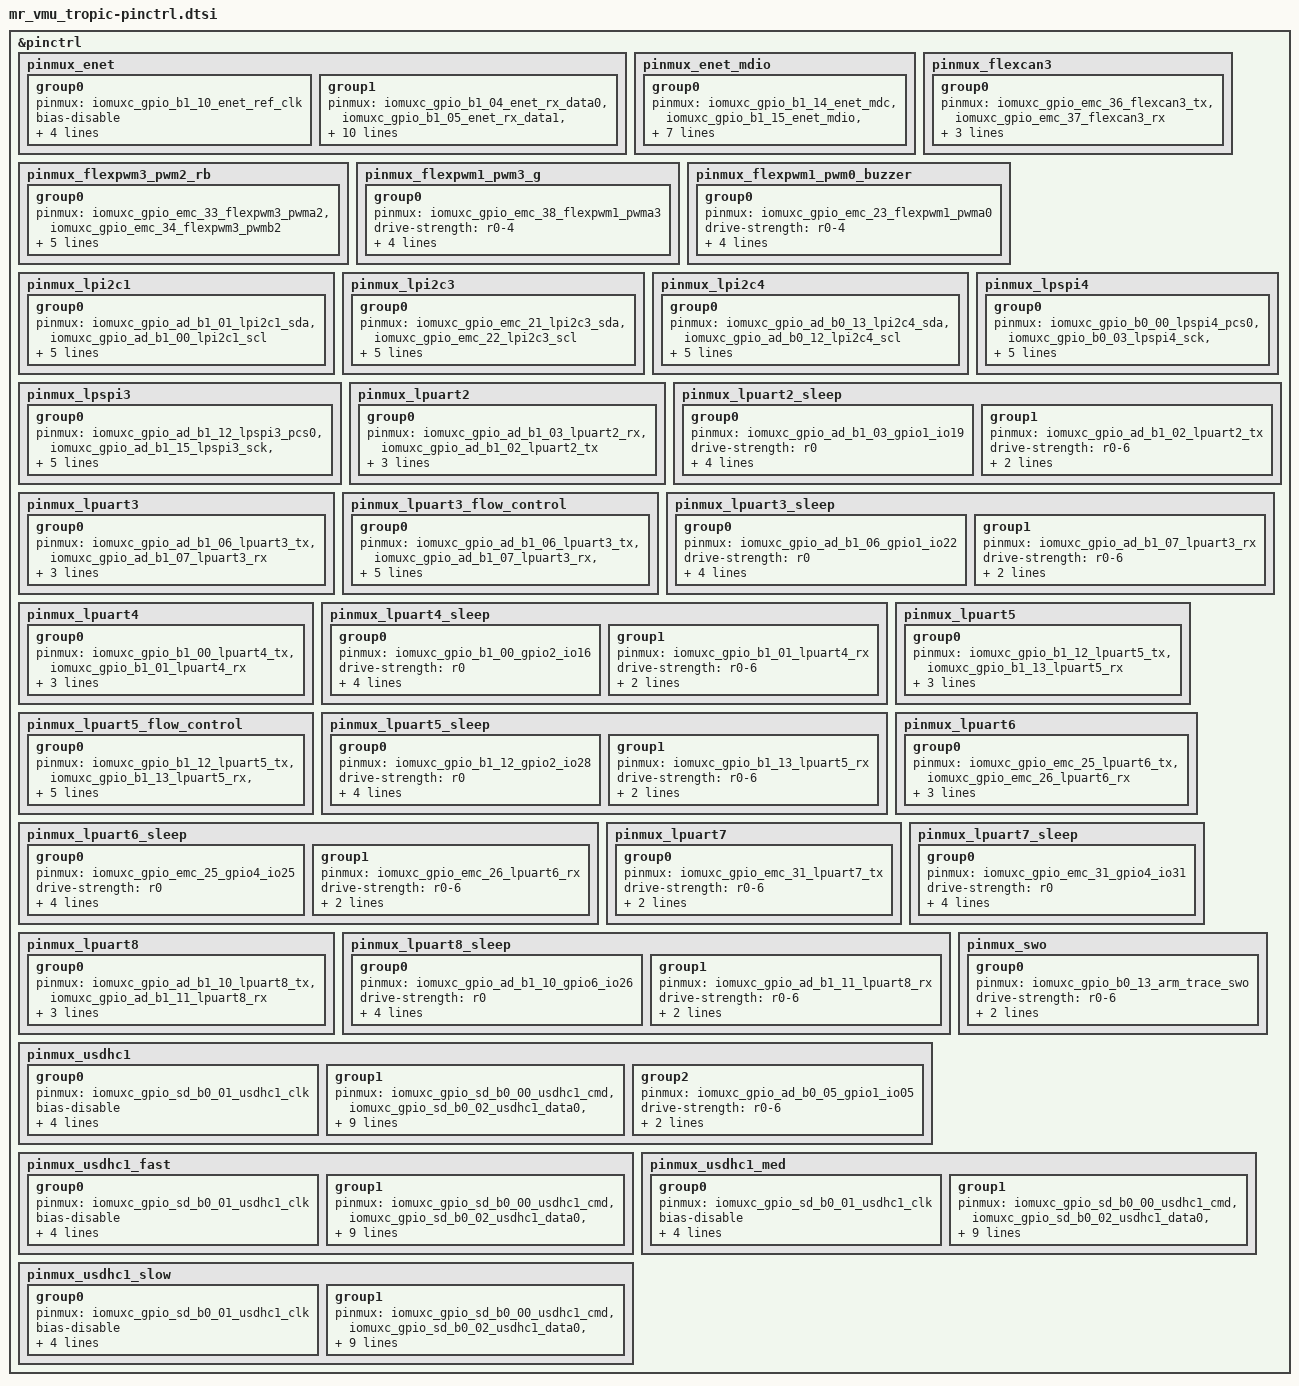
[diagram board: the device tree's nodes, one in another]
/*
 * Copyright (c) 2022, NXP
 * Copyright (c) 2026 CogniPilot Foundation
 * SPDX-License-Identifier: Apache-2.0
 *
 * Note: File generated by gen_board_pinctrl.py
 * from mr_vmu_tropic.mex
 */

#include <nxp/nxp_imx/rt/mimxrt1064dvl6a-pinctrl.dtsi>

&pinctrl {
	pinmux_enet: pinmux_enet {
		group0 {
			pinmux = <&iomuxc_gpio_b1_10_enet_ref_clk>;
			bias-disable;
			drive-strength = "r0-6";
			slew-rate = "fast";
			nxp,speed = "50-mhz";
			input-enable;
		};

		group1 {
			pinmux = <&iomuxc_gpio_b1_04_enet_rx_data0>,
				 <&iomuxc_gpio_b1_05_enet_rx_data1>,
				 <&iomuxc_gpio_b1_06_enet_rx_en>,
				 <&iomuxc_gpio_b1_07_enet_tx_data0>,
				 <&iomuxc_gpio_b1_08_enet_tx_data1>,
				 <&iomuxc_gpio_b1_09_enet_tx_en>,
				 <&iomuxc_gpio_b1_11_enet_rx_er>;
			drive-strength = "r0-5";
			bias-pull-up;
			bias-pull-up-value = "100k";
			slew-rate = "fast";
			nxp,speed = "200-mhz";
		};
	};

	pinmux_enet_mdio: pinmux_enet_mdio {
		group0 {
			pinmux = <&iomuxc_gpio_b1_14_enet_mdc>,
				 <&iomuxc_gpio_b1_15_enet_mdio>,
				 <&iomuxc_gpio_b0_14_gpio2_io14>,
				 <&iomuxc_gpio_b0_15_gpio2_io15>;
			drive-strength = "r0-5";
			bias-pull-up;
			bias-pull-up-value = "100k";
			slew-rate = "fast";
			nxp,speed = "200-mhz";
		};
	};

	pinmux_flexcan3: pinmux_flexcan3 {
		group0 {
			pinmux = <&iomuxc_gpio_emc_36_flexcan3_tx>,
				 <&iomuxc_gpio_emc_37_flexcan3_rx>;
			drive-strength = "r0-6";
			slew-rate = "slow";
			nxp,speed = "100-mhz";
		};
	};

	/* flexpwm output for board RGB Red/Blue LED */
	pinmux_flexpwm3_pwm2_rb: pinmux_flexpwm3_pwm2_rb {
		group0 {
			pinmux = <&iomuxc_gpio_emc_33_flexpwm3_pwma2>,
				 <&iomuxc_gpio_emc_34_flexpwm3_pwmb2>;
			drive-strength = "r0-4";
			bias-pull-up;
			bias-pull-up-value = "47k";
			slew-rate = "slow";
			nxp,speed = "100-mhz";
		};
	};

	/* flexpwm output for board RGB Green LED */
	pinmux_flexpwm1_pwm3_g: pinmux_flexpwm1_pwm3_g {
		group0 {
			pinmux = <&iomuxc_gpio_emc_38_flexpwm1_pwma3>;
			drive-strength = "r0-4";
			bias-pull-up;
			bias-pull-up-value = "47k";
			slew-rate = "slow";
			nxp,speed = "100-mhz";
		};
	};

	/* flexpwm output for buzzer */
	pinmux_flexpwm1_pwm0_buzzer: pinmux_flexpwm1_pwm0_buzzer {
		group0 {
			pinmux = <&iomuxc_gpio_emc_23_flexpwm1_pwma0>;
			drive-strength = "r0-4";
			bias-pull-up;
			bias-pull-up-value = "47k";
			slew-rate = "slow";
			nxp,speed = "100-mhz";
		};
	};

	pinmux_lpi2c1: pinmux_lpi2c1 {
		group0 {
			pinmux = <&iomuxc_gpio_ad_b1_01_lpi2c1_sda>,
				 <&iomuxc_gpio_ad_b1_00_lpi2c1_scl>;
			drive-strength = "r0-6";
			drive-open-drain;
			slew-rate = "slow";
			nxp,speed = "100-mhz";
			input-enable;
		};
	};

	pinmux_lpi2c3: pinmux_lpi2c3 {
		group0 {
			pinmux = <&iomuxc_gpio_emc_21_lpi2c3_sda>,
				 <&iomuxc_gpio_emc_22_lpi2c3_scl>;
			drive-strength = "r0-6";
			drive-open-drain;
			slew-rate = "slow";
			nxp,speed = "100-mhz";
			input-enable;
		};
	};

	pinmux_lpi2c4: pinmux_lpi2c4 {
		group0 {
			pinmux = <&iomuxc_gpio_ad_b0_13_lpi2c4_sda>,
				 <&iomuxc_gpio_ad_b0_12_lpi2c4_scl>;
			drive-strength = "r0-6";
			drive-open-drain;
			slew-rate = "slow";
			nxp,speed = "100-mhz";
			input-enable;
		};
	};

	pinmux_lpspi3: pinmux_lpspi3 {
		group0 {
			pinmux = <&iomuxc_gpio_ad_b1_12_lpspi3_pcs0>,
				 <&iomuxc_gpio_ad_b1_15_lpspi3_sck>,
				 <&iomuxc_gpio_ad_b1_13_lpspi3_sdi>,
				 <&iomuxc_gpio_ad_b1_14_lpspi3_sdo>;
			drive-strength = "r0-6";
			slew-rate = "slow";
			nxp,speed = "100-mhz";
		};
	};

	pinmux_lpspi4: pinmux_lpspi4 {
		group0 {
			pinmux = <&iomuxc_gpio_b0_00_lpspi4_pcs0>,
				 <&iomuxc_gpio_b0_03_lpspi4_sck>,
				 <&iomuxc_gpio_b0_01_lpspi4_sdi>,
				 <&iomuxc_gpio_b0_02_lpspi4_sdo>;
			drive-strength = "r0-6";
			slew-rate = "slow";
			nxp,speed = "100-mhz";
		};
	};

	/* GPS */
	pinmux_lpuart2: pinmux_lpuart2 {
		group0 {
			pinmux = <&iomuxc_gpio_ad_b1_03_lpuart2_rx>,
				 <&iomuxc_gpio_ad_b1_02_lpuart2_tx>;
			drive-strength = "r0-6";
			slew-rate = "slow";
			nxp,speed = "100-mhz";
		};
	};

	pinmux_lpuart2_sleep: pinmux_lpuart2_sleep {
		group0 {
			pinmux = <&iomuxc_gpio_ad_b1_03_gpio1_io19>;
			drive-strength = "r0";
			bias-pull-up;
			bias-pull-up-value = "100k";
			slew-rate = "slow";
			nxp,speed = "50-mhz";
		};

		group1 {
			pinmux = <&iomuxc_gpio_ad_b1_02_lpuart2_tx>;
			drive-strength = "r0-6";
			slew-rate = "slow";
			nxp,speed = "100-mhz";
		};
	};

	/* Telem 1 */
	pinmux_lpuart3: pinmux_lpuart3 {
		group0 {
			pinmux = <&iomuxc_gpio_ad_b1_06_lpuart3_tx>,
				 <&iomuxc_gpio_ad_b1_07_lpuart3_rx>;
			drive-strength = "r0-6";
			slew-rate = "slow";
			nxp,speed = "100-mhz";
		};
	};

	/* Flow control for lpuart3 */
	pinmux_lpuart3_flow_control: pinmux_lpuart3_flow_control {
		group0 {
			pinmux = <&iomuxc_gpio_ad_b1_06_lpuart3_tx>,
				 <&iomuxc_gpio_ad_b1_07_lpuart3_rx>,
				 <&iomuxc_gpio_ad_b1_04_lpuart3_cts_b>,
				 <&iomuxc_gpio_ad_b1_05_lpuart3_rts_b>;
			drive-strength = "r0-6";
			slew-rate = "slow";
			nxp,speed = "100-mhz";
		};
	};

	pinmux_lpuart3_sleep: pinmux_lpuart3_sleep {
		group0 {
			pinmux = <&iomuxc_gpio_ad_b1_06_gpio1_io22>;
			drive-strength = "r0";
			bias-pull-up;
			bias-pull-up-value = "100k";
			slew-rate = "slow";
			nxp,speed = "100-mhz";
		};

		group1 {
			pinmux = <&iomuxc_gpio_ad_b1_07_lpuart3_rx>;
			drive-strength = "r0-6";
			slew-rate = "slow";
			nxp,speed = "100-mhz";
		};
	};

	/* AUX */
	pinmux_lpuart4: pinmux_lpuart4 {
		group0 {
			pinmux = <&iomuxc_gpio_b1_00_lpuart4_tx>,
				 <&iomuxc_gpio_b1_01_lpuart4_rx>;
			drive-strength = "r0-6";
			slew-rate = "slow";
			nxp,speed = "100-mhz";
		};
	};

	pinmux_lpuart4_sleep: pinmux_lpuart4_sleep {
		group0 {
			pinmux = <&iomuxc_gpio_b1_00_gpio2_io16>;
			drive-strength = "r0";
			bias-pull-up;
			bias-pull-up-value = "100k";
			slew-rate = "slow";
			nxp,speed = "100-mhz";
		};

		group1 {
			pinmux = <&iomuxc_gpio_b1_01_lpuart4_rx>;
			drive-strength = "r0-6";
			slew-rate = "slow";
			nxp,speed = "100-mhz";
		};
	};

	/* Telem 2 */
	pinmux_lpuart5: pinmux_lpuart5 {
		group0 {
			pinmux = <&iomuxc_gpio_b1_12_lpuart5_tx>,
				 <&iomuxc_gpio_b1_13_lpuart5_rx>;
			drive-strength = "r0-6";
			slew-rate = "slow";
			nxp,speed = "100-mhz";
		};
	};

	/* Flow control for lpuart5 */
	pinmux_lpuart5_flow_control: pinmux_lpuart5_flow_control {
		group0 {
			pinmux = <&iomuxc_gpio_b1_12_lpuart5_tx>,
				 <&iomuxc_gpio_b1_13_lpuart5_rx>,
				 <&iomuxc_gpio_emc_28_lpuart5_cts_b>,
				 <&iomuxc_gpio_emc_27_lpuart5_rts_b>;
			drive-strength = "r0-6";
			slew-rate = "slow";
			nxp,speed = "100-mhz";
		};
	};

	pinmux_lpuart5_sleep: pinmux_lpuart5_sleep {
		group0 {
			pinmux = <&iomuxc_gpio_b1_12_gpio2_io28>;
			drive-strength = "r0";
			bias-pull-up;
			bias-pull-up-value = "100k";
			slew-rate = "slow";
			nxp,speed = "100-mhz";
		};

		group1 {
			pinmux = <&iomuxc_gpio_b1_13_lpuart5_rx>;
			drive-strength = "r0-6";
			slew-rate = "slow";
			nxp,speed = "100-mhz";
		};
	};

	/* Console / Shell / Debug */
	pinmux_lpuart6: pinmux_lpuart6 {
		group0 {
			pinmux = <&iomuxc_gpio_emc_25_lpuart6_tx>,
				 <&iomuxc_gpio_emc_26_lpuart6_rx>;
			drive-strength = "r0-6";
			slew-rate = "slow";
			nxp,speed = "100-mhz";
		};
	};

	pinmux_lpuart6_sleep: pinmux_lpuart6_sleep {
		group0 {
			pinmux = <&iomuxc_gpio_emc_25_gpio4_io25>;
			drive-strength = "r0";
			bias-pull-up;
			bias-pull-up-value = "100k";
			slew-rate = "slow";
			nxp,speed = "100-mhz";
		};

		group1 {
			pinmux = <&iomuxc_gpio_emc_26_lpuart6_rx>;
			drive-strength = "r0-6";
			slew-rate = "slow";
			nxp,speed = "100-mhz";
		};
	};

	/* ESC onewire */
	pinmux_lpuart7: pinmux_lpuart7 {
		group0 {
			pinmux = <&iomuxc_gpio_emc_31_lpuart7_tx>;
			drive-strength = "r0-6";
			slew-rate = "slow";
			nxp,speed = "100-mhz";
		};
	};

	pinmux_lpuart7_sleep: pinmux_lpuart7_sleep {
		group0 {
			pinmux = <&iomuxc_gpio_emc_31_gpio4_io31>;
			drive-strength = "r0";
			bias-pull-up;
			bias-pull-up-value = "100k";
			slew-rate = "slow";
			nxp,speed = "100-mhz";
		};
	};

	/* RC Input */
	pinmux_lpuart8: pinmux_lpuart8 {
		group0 {
			pinmux = <&iomuxc_gpio_ad_b1_10_lpuart8_tx>,
				 <&iomuxc_gpio_ad_b1_11_lpuart8_rx>;
			drive-strength = "r0-6";
			slew-rate = "slow";
			nxp,speed = "100-mhz";
		};
	};

	pinmux_lpuart8_sleep: pinmux_lpuart8_sleep {
		group0 {
			pinmux = <&iomuxc_gpio_ad_b1_10_gpio6_io26>;
			drive-strength = "r0";
			bias-pull-up;
			bias-pull-up-value = "100k";
			slew-rate = "slow";
			nxp,speed = "100-mhz";
		};

		group1 {
			pinmux = <&iomuxc_gpio_ad_b1_11_lpuart8_rx>;
			drive-strength = "r0-6";
			slew-rate = "slow";
			nxp,speed = "100-mhz";
		};
	};

	/* note swo is configured with a cpu frequency of 132mhz and swo frequency of 7500khz */
	pinmux_swo: pinmux_swo {
		group0 {
			pinmux = <&iomuxc_gpio_b0_13_arm_trace_swo>;
			drive-strength = "r0-6";
			slew-rate = "fast";
			nxp,speed = "100-mhz";
		};
	};

	pinmux_usdhc1: pinmux_usdhc1 {
		group0 {
			pinmux = <&iomuxc_gpio_sd_b0_01_usdhc1_clk>;
			bias-disable;
			drive-strength = "r0";
			input-schmitt-enable;
			slew-rate = "fast";
			nxp,speed = "100-mhz";
		};

		group1 {
			pinmux = <&iomuxc_gpio_sd_b0_00_usdhc1_cmd>,
				 <&iomuxc_gpio_sd_b0_02_usdhc1_data0>,
				 <&iomuxc_gpio_sd_b0_03_usdhc1_data1>,
				 <&iomuxc_gpio_sd_b0_04_usdhc1_data2>,
				 <&iomuxc_gpio_sd_b0_05_usdhc1_data3>;
			drive-strength = "r0";
			input-schmitt-enable;
			bias-pull-up;
			bias-pull-up-value = "47k";
			slew-rate = "fast";
			nxp,speed = "100-mhz";
		};

		group2 {
			pinmux = <&iomuxc_gpio_ad_b0_05_gpio1_io05>;
			drive-strength = "r0-6";
			slew-rate = "slow";
			nxp,speed = "100-mhz";
		};
	};

	/* fast pinmux settings for USDHC (over 100 Mhz) */
	pinmux_usdhc1_fast: pinmux_usdhc1_fast {
		group0 {
			pinmux = <&iomuxc_gpio_sd_b0_01_usdhc1_clk>;
			bias-disable;
			drive-strength = "r0-7";
			input-schmitt-enable;
			slew-rate = "fast";
			nxp,speed = "200-mhz";
		};

		group1 {
			pinmux = <&iomuxc_gpio_sd_b0_00_usdhc1_cmd>,
				 <&iomuxc_gpio_sd_b0_02_usdhc1_data0>,
				 <&iomuxc_gpio_sd_b0_03_usdhc1_data1>,
				 <&iomuxc_gpio_sd_b0_04_usdhc1_data2>,
				 <&iomuxc_gpio_sd_b0_05_usdhc1_data3>;
			drive-strength = "r0-7";
			input-schmitt-enable;
			bias-pull-up;
			bias-pull-up-value = "47k";
			slew-rate = "fast";
			nxp,speed = "200-mhz";
		};
	};

	/* medium pinmux settings for USDHC (under 100 Mhz) */
	pinmux_usdhc1_med: pinmux_usdhc1_med {
		group0 {
			pinmux = <&iomuxc_gpio_sd_b0_01_usdhc1_clk>;
			bias-disable;
			drive-strength = "r0-7";
			input-schmitt-enable;
			slew-rate = "fast";
			nxp,speed = "100-mhz";
		};

		group1 {
			pinmux = <&iomuxc_gpio_sd_b0_00_usdhc1_cmd>,
				 <&iomuxc_gpio_sd_b0_02_usdhc1_data0>,
				 <&iomuxc_gpio_sd_b0_03_usdhc1_data1>,
				 <&iomuxc_gpio_sd_b0_04_usdhc1_data2>,
				 <&iomuxc_gpio_sd_b0_05_usdhc1_data3>;
			drive-strength = "r0-7";
			input-schmitt-enable;
			bias-pull-up;
			bias-pull-up-value = "47k";
			slew-rate = "fast";
			nxp,speed = "100-mhz";
		};
	};

	/* slow pinmux settings for USDHC (under 50 Mhz) */
	pinmux_usdhc1_slow: pinmux_usdhc1_slow {
		group0 {
			pinmux = <&iomuxc_gpio_sd_b0_01_usdhc1_clk>;
			bias-disable;
			drive-strength = "r0-7";
			input-schmitt-enable;
			slew-rate = "fast";
			nxp,speed = "50-mhz";
		};

		group1 {
			pinmux = <&iomuxc_gpio_sd_b0_00_usdhc1_cmd>,
				 <&iomuxc_gpio_sd_b0_02_usdhc1_data0>,
				 <&iomuxc_gpio_sd_b0_03_usdhc1_data1>,
				 <&iomuxc_gpio_sd_b0_04_usdhc1_data2>,
				 <&iomuxc_gpio_sd_b0_05_usdhc1_data3>;
			drive-strength = "r0-7";
			input-schmitt-enable;
			bias-pull-up;
			bias-pull-up-value = "47k";
			slew-rate = "fast";
			nxp,speed = "50-mhz";
		};
	};
};
